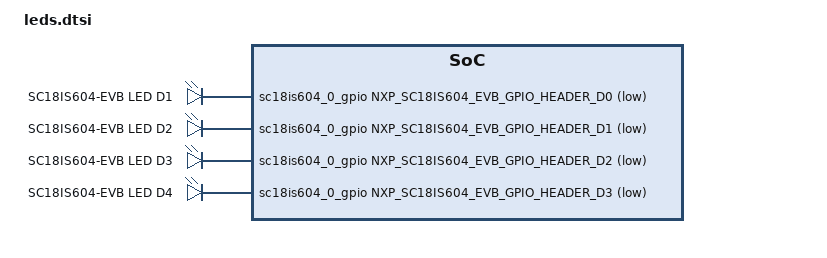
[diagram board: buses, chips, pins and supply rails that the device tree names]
/*
 * SPDX-FileCopyrightText: Copyright (c) 2024-2026 TiaC Systems
 * SPDX-License-Identifier: Apache-2.0
 */

#include <zephyr/dt-bindings/gpio/gpio.h>

#include <zephyr/dt-bindings/gpio/nxp-sc18is604-evb-gpio-header.h>

/ {
	nxp_sc18is604_evb_gpio_leds: sc18is604-0-gpio-leds {
		compatible = "gpio-leds";

		/* Green LED D1 is connected to IO0 */
		nxp_sc18is604_evb_green_led_d1: sc18is604-0-gpio-0-led {
			gpios = <&sc18is604_0_gpio NXP_SC18IS604_EVB_GPIO_HEADER_D0
								GPIO_ACTIVE_LOW>;
			label = "SC18IS604-EVB LED D1";
		};

		/* Green LED D2 is connected to IO1 */
		nxp_sc18is604_evb_green_led_d2: sc18is604-0-gpio-1-led {
			gpios = <&sc18is604_0_gpio NXP_SC18IS604_EVB_GPIO_HEADER_D1
								GPIO_ACTIVE_LOW>;
			label = "SC18IS604-EVB LED D2";
		};

		/* Green LED D3 is connected to IO2 */
		nxp_sc18is604_evb_green_led_d3: sc18is604-0-gpio-2-led {
			gpios = <&sc18is604_0_gpio NXP_SC18IS604_EVB_GPIO_HEADER_D2
								GPIO_ACTIVE_LOW>;
			label = "SC18IS604-EVB LED D3";
		};

		/* Green LED D4 is connected to IO3 */
		nxp_sc18is604_evb_green_led_d4: sc18is604-0-gpio-3-led {
			gpios = <&sc18is604_0_gpio NXP_SC18IS604_EVB_GPIO_HEADER_D3
								GPIO_ACTIVE_LOW>;
			label = "SC18IS604-EVB LED D4";
		};

		/*
		 * Green LED D10 is connected to IO4, which can
		 * only be used as input and can not configured.
		 */
	};
};
